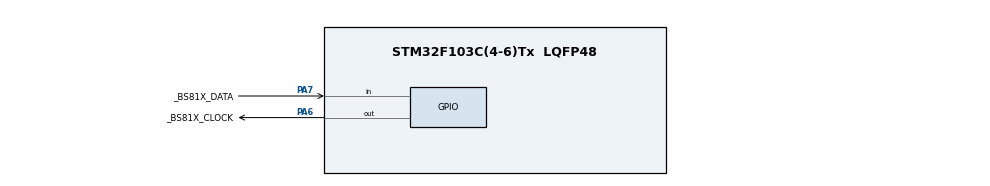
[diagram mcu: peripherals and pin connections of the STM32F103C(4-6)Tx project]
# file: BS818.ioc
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Mcu.Family=STM32F1
Mcu.Name=STM32F103C(4-6)Tx
Mcu.Package=LQFP48
NVIC.PriorityGroup=NVIC_PRIORITYGROUP_4
PA6.GPIO_Label=_BS81X_CLOCK
PA6.Signal=GPIO_Output
PA7.GPIO_Label=_BS81X_DATA
PA7.Signal=GPIO_Input
ProjectManager.HeapSize=0x200
ProjectManager.StackSize=0x400
ProjectManager.TargetToolchain=STM32CubeIDE
RCC.APB1Freq_Value=8000000
RCC.APB2Freq_Value=8000000
VP_SYS_VS_ND.Mode=No_Debug
board=custom

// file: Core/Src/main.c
/* USER CODE BEGIN Header */
/**
  ******************************************************************************
  * @file           : main.c
  * @brief          : Main program body
  ******************************************************************************
  * @attention
  *
  * Copyright (c) 2024 STMicroelectronics.
  * All rights reserved.
  *
  * This software is licensed under terms that can be found in the LICENSE file
  * in the root directory of this software component.
  * If no LICENSE file comes with this software, it is provided AS-IS.
  *
  ******************************************************************************
  */
/* USER CODE END Header */
#include "main.h"

/* USER CODE BEGIN Includes */
#include "Bs81x.h"
#include "Bs81x_Conf.h"
#include "TM1638.h"
#include "TM1638_platform.h"
/* USER CODE END Includes */

/* USER CODE BEGIN PD */
TM1638_Handler_t Handler = {0};
uint8_t Buffer[7] = {0};
uint16_t a;

int minutes = 25;
int seconds = 0;
bool flag_timeout=false;
/* USER CODE END PD */

void SystemClock_Config(void);
static void MX_GPIO_Init(void);

/* USER CODE BEGIN 0 */

void printLCD(int minutes, int second){
    Buffer[2] = minutes % 10;
    Buffer[0] = (minutes / 10) % 10;
    Buffer[6] = second % 10;
    Buffer[4] = (second / 10) % 10;

	Buffer[6] |= TM1638DecimalPoint;
	Buffer[4] |= TM1638DecimalPoint;

	TM1638_SetMultipleDigit_HEX(&Handler, Buffer, 0, 7);
}
void setTimeAuto(void){
	while (minutes >= 0) {
		printLCD(minutes,seconds);
		HAL_Delay(100);
		if (seconds == 0) {
			if (minutes == 0){
				flag_timeout=true;
				break;
			}
			minutes--;
			seconds = 59;
		} else {
			seconds--;
		}
	}
}
/* USER CODE END 0 */

int main(void)
{

  /* MCU Configuration--------------------------------------------------------*/

  /* Reset of all peripherals, Initializes the Flash interface and the Systick. */
  HAL_Init();

  /* Configure the system clock */
  SystemClock_Config();

  /* Initialize all configured peripherals */
  MX_GPIO_Init();
  /* USER CODE BEGIN 2 */
  Bs81x_Init();

  TM1638_Platform_Init(&Handler);
  TM1638_Init(&Handler, TM1638DisplayTypeComCathode);
  TM1638_ConfigDisplay(&Handler, 7, TM1638DisplayStateON);
  /* USER CODE END 2 */

  /* Infinite loop */
  while (1)
  {
	  setTimeAuto();
    /* USER CODE BEGIN 3 */
  }
  TM1638_DeInit(&Handler);

  /* USER CODE END 3 */
}

void SystemClock_Config(void)
{
  RCC_OscInitTypeDef RCC_OscInitStruct = {0};
  RCC_ClkInitTypeDef RCC_ClkInitStruct = {0};

  /** Initializes the RCC Oscillators according to the specified parameters
  * in the RCC_OscInitTypeDef structure.
  */
  RCC_OscInitStruct.OscillatorType = RCC_OSCILLATORTYPE_HSI;
  RCC_OscInitStruct.HSIState = RCC_HSI_ON;
  RCC_OscInitStruct.HSICalibrationValue = RCC_HSICALIBRATION_DEFAULT;
  RCC_OscInitStruct.PLL.PLLState = RCC_PLL_NONE;
  if (HAL_RCC_OscConfig(&RCC_OscInitStruct) != HAL_OK)
  {
    Error_Handler();
  }

  /** Initializes the CPU, AHB and APB buses clocks
  */
  RCC_ClkInitStruct.ClockType = RCC_CLOCKTYPE_HCLK|RCC_CLOCKTYPE_SYSCLK
                              |RCC_CLOCKTYPE_PCLK1|RCC_CLOCKTYPE_PCLK2;
  RCC_ClkInitStruct.SYSCLKSource = RCC_SYSCLKSOURCE_HSI;
  RCC_ClkInitStruct.AHBCLKDivider = RCC_SYSCLK_DIV1;
  RCC_ClkInitStruct.APB1CLKDivider = RCC_HCLK_DIV1;
  RCC_ClkInitStruct.APB2CLKDivider = RCC_HCLK_DIV1;

  if (HAL_RCC_ClockConfig(&RCC_ClkInitStruct, FLASH_LATENCY_0) != HAL_OK)
  {
    Error_Handler();
  }
}

static void MX_GPIO_Init(void)
{
  GPIO_InitTypeDef GPIO_InitStruct = {0};

  /* GPIO Ports Clock Enable */
  __HAL_RCC_GPIOA_CLK_ENABLE();

  /*Configure GPIO pin Output Level */
  HAL_GPIO_WritePin(_BS81X_CLOCK_GPIO_Port, _BS81X_CLOCK_Pin, GPIO_PIN_RESET);

  /*Configure GPIO pin : _BS81X_CLOCK_Pin */
  GPIO_InitStruct.Pin = _BS81X_CLOCK_Pin;
  GPIO_InitStruct.Mode = GPIO_MODE_OUTPUT_PP;
  GPIO_InitStruct.Pull = GPIO_NOPULL;
  GPIO_InitStruct.Speed = GPIO_SPEED_FREQ_LOW;
  HAL_GPIO_Init(_BS81X_CLOCK_GPIO_Port, &GPIO_InitStruct);

  /*Configure GPIO pin : _BS81X_DATA_Pin */
  GPIO_InitStruct.Pin = _BS81X_DATA_Pin;
  GPIO_InitStruct.Mode = GPIO_MODE_INPUT;
  GPIO_InitStruct.Pull = GPIO_NOPULL;
  HAL_GPIO_Init(_BS81X_DATA_GPIO_Port, &GPIO_InitStruct);

}

void Error_Handler(void)
{
  __disable_irq();
  while (1)
  {
  }
}
